# RP2350 register map
Vendor: Raspberry Pi; Series: RP; File version: 0.1
CPU: CM33 r1p0, little endian, MPU, FPU, DSP, VTOR, 4 interrupt priority bits, 52 interrupts, 8 SAU regions
Registers are 32-bit, read-write, reset 0x0 unless marked. A register's access mark holds for its fields unless they carry their own. Offsets are from the block's base; [hi:lo] are bit positions; {n}, {i} and the like mark numbered series; 'fields as' and 'values as' point back to an identical list.

## CLOCKS
Base 0x40010000
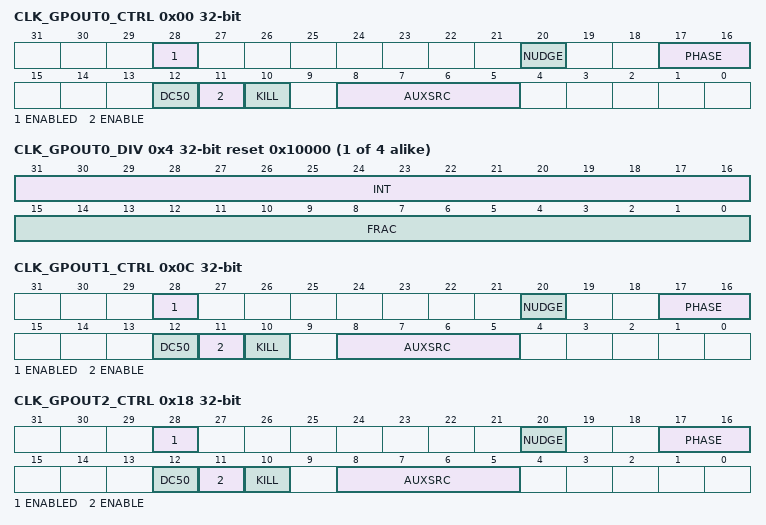
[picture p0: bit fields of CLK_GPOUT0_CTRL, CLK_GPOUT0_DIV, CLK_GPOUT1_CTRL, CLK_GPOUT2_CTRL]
0x00 CLK_GPOUT0_CTRL — Clock control, can be changed on-the-fly (except for auxsrc)
  [28] ENABLED ro — clock generator is enabled
  [20] NUDGE — An edge on this signal shifts the phase of the output by 1 cycle of the input clock This can be done at any time
  [17:16] PHASE — This delays the enable signal by up to 3 cycles of the input clock This must be set before the clock is enabled to have any effect
  [12] DC50 — Enables duty cycle correction for odd divisors, can be changed on-the-fly
  [11] ENABLE — Starts and stops the clock generator cleanly
  [10] KILL — Asynchronously kills the clock generator, enable must be set low before deasserting kill
  [8:5] AUXSRC — Selects the auxiliary clock source, will glitch when switching
    0=clksrc_pll_sys; 1=clksrc_gpin0; 2=clksrc_gpin1; 3=clksrc_pll_usb; 4=clksrc_pll_usb_primary_ref_opcg; 5=rosc_clksrc; 6=xosc_clksrc; 7=lposc_clksrc; 8=clk_sys; 9=clk_usb; 10=clk_adc; 11=clk_ref; 12=clk_peri; 13=clk_hstx; 14=otp_clk2fc
{0x4+0xC*i} CLK_GPOUT{i}_DIV reset 0x10000 (i=0..3)
  [31:16] INT — Integer part of clock divisor, 0 -> max+1, can be changed on-the-fly
  [15:0] FRAC — Fractional component of the divisor, can be changed on-the-fly
{0x8+0xC*i} CLK_GPOUT{i}_SELECTED reset 0x1 (i=0..3) — Indicates which src is currently selected (one-hot)
  [0] CLK_GPOUT{i}_SELECTED ro — This slice does not have a glitchless mux (only the AUX_SRC field is present, not SRC) so this register is hardwired to 0x1.
0x0C CLK_GPOUT1_CTRL — Clock control, can be changed on-the-fly (except for auxsrc)
  fields as CLK_GPOUT0_CTRL
0x18 CLK_GPOUT2_CTRL — Clock control, can be changed on-the-fly (except for auxsrc)
  [28] ENABLED ro — clock generator is enabled
  [20] NUDGE — An edge on this signal shifts the phase of the output by 1 cycle of the input clock This can be done at any time
  [17:16] PHASE — This delays the enable signal by up to 3 cycles of the input clock This must be set before the clock is enabled to have any effect
  [12] DC50 — Enables duty cycle correction for odd divisors, can be changed on-the-fly
  [11] ENABLE — Starts and stops the clock generator cleanly
  [10] KILL — Asynchronously kills the clock generator, enable must be set low before deasserting kill
  [8:5] AUXSRC — Selects the auxiliary clock source, will glitch when switching
    0=clksrc_pll_sys; 1=clksrc_gpin0; 2=clksrc_gpin1; 3=clksrc_pll_usb; 4=clksrc_pll_usb_primary_ref_opcg; 5=rosc_clksrc_ph; 6=xosc_clksrc; 7=lposc_clksrc; 8=clk_sys; 9=clk_usb; 10=clk_adc; 11=clk_ref; 12=clk_peri; 13=clk_hstx; 14=otp_clk2fc
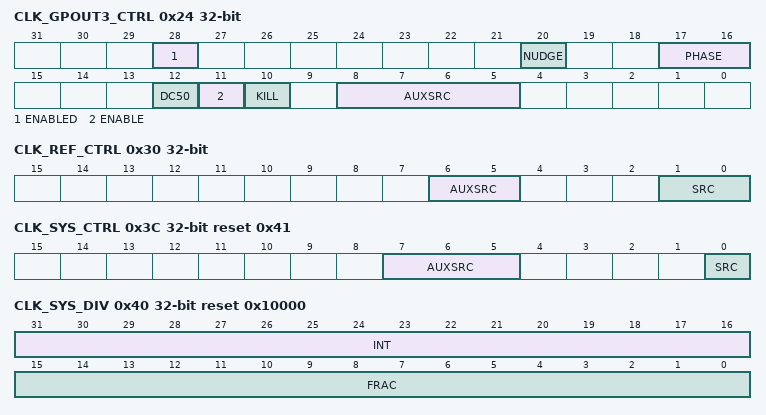
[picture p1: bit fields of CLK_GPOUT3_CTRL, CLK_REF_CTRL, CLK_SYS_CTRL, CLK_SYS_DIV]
0x24 CLK_GPOUT3_CTRL — Clock control, can be changed on-the-fly (except for auxsrc)
  fields as CLK_GPOUT2_CTRL
0x30 CLK_REF_CTRL — Clock control, can be changed on-the-fly (except for auxsrc)
  [6:5] AUXSRC — Selects the auxiliary clock source, will glitch when switching
    0=clksrc_pll_usb; 1=clksrc_gpin0; 2=clksrc_gpin1; 3=clksrc_pll_usb_primary_ref_opcg
  [1:0] SRC — Selects the clock source glitchlessly, can be changed on-the-fly
    0=rosc_clksrc_ph; 1=clksrc_clk_ref_aux; 2=xosc_clksrc; 3=lposc_clksrc
0x34 CLK_REF_DIV reset 0x10000
  [23:16] INT — Integer part of clock divisor, 0 -> max+1, can be changed on-the-fly
0x38 CLK_REF_SELECTED reset 0x1 — Indicates which src is currently selected (one-hot)
  [3:0] CLK_REF_SELECTED ro — The glitchless multiplexer does not switch instantaneously (to avoid glitches), so software should poll this register to wait for the switch to complete. This register contains one decoded bit for each of the clock sources enumerated in the CTRL SRC field. At most one of these bits will be set at any time, indicating that clock is currently present at the output of the glitchless mux. Whilst switching is in progress, this register may briefly show all-0s.
0x3C CLK_SYS_CTRL reset 0x41 — Clock control, can be changed on-the-fly (except for auxsrc)
  [7:5] AUXSRC — Selects the auxiliary clock source, will glitch when switching
    0=clksrc_pll_sys; 1=clksrc_pll_usb; 2=rosc_clksrc; 3=xosc_clksrc; 4=clksrc_gpin0; 5=clksrc_gpin1
  [0] SRC — Selects the clock source glitchlessly, can be changed on-the-fly
    0=clk_ref; 1=clksrc_clk_sys_aux
0x40 CLK_SYS_DIV reset 0x10000
  fields as CLK_GPOUT0_DIV
0x44 CLK_SYS_SELECTED reset 0x1 — Indicates which src is currently selected (one-hot)
  [1:0] CLK_SYS_SELECTED ro — The glitchless multiplexer does not switch instantaneously (to avoid glitches), so software should poll this register to wait for the switch to complete. This register contains one decoded bit for each of the clock sources enumerated in the CTRL SRC field. At most one of these bits will be set at any time, indicating that clock is currently present at the output of the glitchless mux. Whilst switching is in progress, this register may briefly show all-0s.
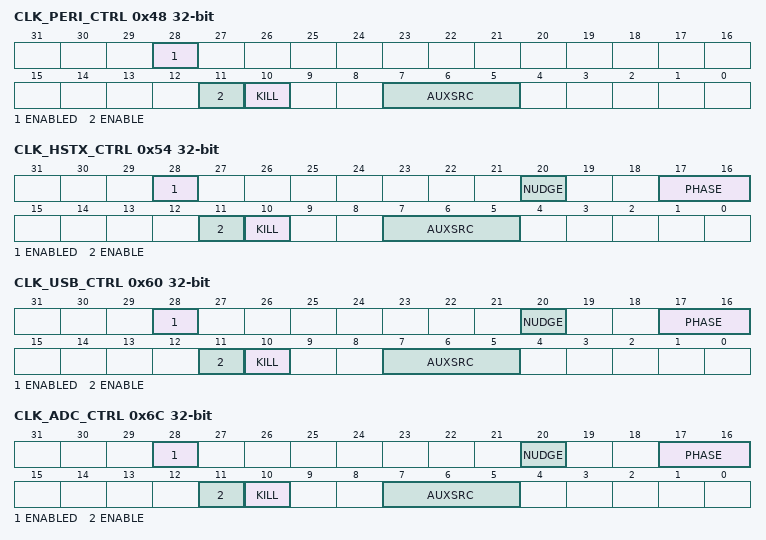
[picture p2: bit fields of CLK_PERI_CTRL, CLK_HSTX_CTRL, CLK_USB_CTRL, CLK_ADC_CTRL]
0x48 CLK_PERI_CTRL — Clock control, can be changed on-the-fly (except for auxsrc)
  [28] ENABLED ro — clock generator is enabled
  [11] ENABLE — Starts and stops the clock generator cleanly
  [10] KILL — Asynchronously kills the clock generator, enable must be set low before deasserting kill
  [7:5] AUXSRC — Selects the auxiliary clock source, will glitch when switching
    0=clk_sys; 1=clksrc_pll_sys; 2=clksrc_pll_usb; 3=rosc_clksrc_ph; 4=xosc_clksrc; 5=clksrc_gpin0; 6=clksrc_gpin1
0x4C CLK_PERI_DIV reset 0x10000
  [17:16] INT — Integer part of clock divisor, 0 -> max+1, can be changed on-the-fly
0x50 CLK_PERI_SELECTED reset 0x1 — Indicates which src is currently selected (one-hot)
  [0] CLK_PERI_SELECTED ro — This slice does not have a glitchless mux (only the AUX_SRC field is present, not SRC) so this register is hardwired to 0x1.
0x54 CLK_HSTX_CTRL — Clock control, can be changed on-the-fly (except for auxsrc)
  [28] ENABLED ro — clock generator is enabled
  [20] NUDGE — An edge on this signal shifts the phase of the output by 1 cycle of the input clock This can be done at any time
  [17:16] PHASE — This delays the enable signal by up to 3 cycles of the input clock This must be set before the clock is enabled to have any effect
  [11] ENABLE — Starts and stops the clock generator cleanly
  [10] KILL — Asynchronously kills the clock generator, enable must be set low before deasserting kill
  [7:5] AUXSRC — Selects the auxiliary clock source, will glitch when switching
    0=clk_sys; 1=clksrc_pll_sys; 2=clksrc_pll_usb; 3=clksrc_gpin0; 4=clksrc_gpin1
0x58 CLK_HSTX_DIV reset 0x10000
  fields as CLK_PERI_DIV
0x5C CLK_HSTX_SELECTED reset 0x1 — Indicates which src is currently selected (one-hot)
  [0] CLK_HSTX_SELECTED ro — This slice does not have a glitchless mux (only the AUX_SRC field is present, not SRC) so this register is hardwired to 0x1.
0x60 CLK_USB_CTRL — Clock control, can be changed on-the-fly (except for auxsrc)
  [28] ENABLED ro — clock generator is enabled
  [20] NUDGE — An edge on this signal shifts the phase of the output by 1 cycle of the input clock This can be done at any time
  [17:16] PHASE — This delays the enable signal by up to 3 cycles of the input clock This must be set before the clock is enabled to have any effect
  [11] ENABLE — Starts and stops the clock generator cleanly
  [10] KILL — Asynchronously kills the clock generator, enable must be set low before deasserting kill
  [7:5] AUXSRC — Selects the auxiliary clock source, will glitch when switching
    0=clksrc_pll_usb; 1=clksrc_pll_sys; 2=rosc_clksrc_ph; 3=xosc_clksrc; 4=clksrc_gpin0; 5=clksrc_gpin1
0x64 CLK_USB_DIV reset 0x10000
  [19:16] INT — Integer part of clock divisor, 0 -> max+1, can be changed on-the-fly
0x68 CLK_USB_SELECTED reset 0x1 — Indicates which src is currently selected (one-hot)
  [0] CLK_USB_SELECTED ro — This slice does not have a glitchless mux (only the AUX_SRC field is present, not SRC) so this register is hardwired to 0x1.
0x6C CLK_ADC_CTRL — Clock control, can be changed on-the-fly (except for auxsrc)
  fields as CLK_USB_CTRL
0x70 CLK_ADC_DIV reset 0x10000
  fields as CLK_USB_DIV
0x74 CLK_ADC_SELECTED reset 0x1 — Indicates which src is currently selected (one-hot)
  [0] CLK_ADC_SELECTED ro — This slice does not have a glitchless mux (only the AUX_SRC field is present, not SRC) so this register is hardwired to 0x1.
0x78 DFTCLK_XOSC_CTRL
  [1:0] SRC
    0=NULL; 1=clksrc_pll_usb_primary; 2=clksrc_gpin0
0x7C DFTCLK_ROSC_CTRL
  [1:0] SRC
    0=NULL; 1=clksrc_pll_sys_primary_rosc; 2=clksrc_gpin1
0x80 DFTCLK_LPOSC_CTRL
  [1:0] SRC
    0=NULL; 1=clksrc_pll_usb_primary_lposc; 2=clksrc_gpin1
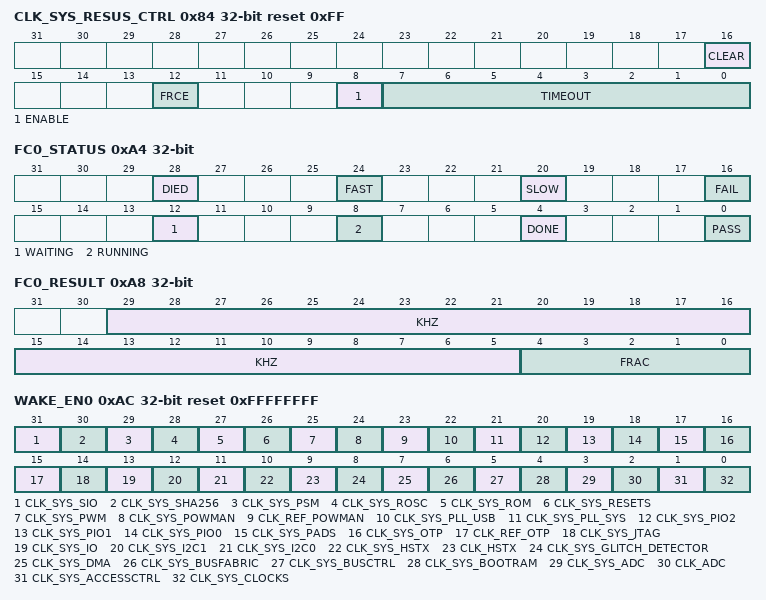
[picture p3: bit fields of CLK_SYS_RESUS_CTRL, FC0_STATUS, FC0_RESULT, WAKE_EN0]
0x84 CLK_SYS_RESUS_CTRL reset 0xFF
  [16] CLEAR — For clearing the resus after the fault that triggered it has been corrected
  [12] FRCE — Force a resus, for test purposes only
  [8] ENABLE — Enable resus
  [7:0] TIMEOUT — This is expressed as a number of clk_ref cycles and must be >= 2x clk_ref_freq/min_clk_tst_freq
0x88 CLK_SYS_RESUS_STATUS
  [0] RESUSSED ro — Clock has been resuscitated, correct the error then send ctrl_clear=1
0x8C FC0_REF_KHZ — Reference clock frequency in kHz
  [19:0] FC0_REF_KHZ
0x90 FC0_MIN_KHZ — Minimum pass frequency in kHz. This is optional. Set to 0 if you are not using the pass/fail flags
  [24:0] FC0_MIN_KHZ
0x94 FC0_MAX_KHZ reset 0x1FFFFFF — Maximum pass frequency in kHz. This is optional. Set to 0x1ffffff if you are not using the pass/fail flags
  [24:0] FC0_MAX_KHZ
0x98 FC0_DELAY reset 0x1 — Delays the start of frequency counting to allow the mux to settle Delay is measured in multiples of the reference clock period
  [2:0] FC0_DELAY
0x9C FC0_INTERVAL reset 0x8 — The test interval is 0.98us * 2**interval, but let's call it 1us * 2**interval The default gives a test interval of 250us
  [3:0] FC0_INTERVAL
0xA0 FC0_SRC — Clock sent to frequency counter, set to 0 when not required Writing to this register initiates the frequency count
  [7:0] FC0_SRC
    0=NULL; 1=pll_sys_clksrc_primary; 2=pll_usb_clksrc_primary; 3=rosc_clksrc; 4=rosc_clksrc_ph; 5=xosc_clksrc; 6=clksrc_gpin0; 7=clksrc_gpin1; 8=clk_ref; 9=clk_sys; 10=clk_peri; 11=clk_usb; 12=clk_adc; 13=clk_hstx; 14=lposc_clksrc; 15=otp_clk2fc; 16=pll_usb_clksrc_primary_dft
0xA4 FC0_STATUS — Frequency counter status
  [28] DIED ro — Test clock stopped during test
  [24] FAST ro — Test clock faster than expected, only valid when status_done=1
  [20] SLOW ro — Test clock slower than expected, only valid when status_done=1
  [16] FAIL ro — Test failed
  [12] WAITING ro — Waiting for test clock to start
  [8] RUNNING ro — Test running
  [4] DONE ro — Test complete
  [0] PASS ro — Test passed
0xA8 FC0_RESULT — Result of frequency measurement, only valid when status_done=1
  [29:5] KHZ ro, [4:0] FRAC ro
0xAC WAKE_EN0 reset 0xFFFFFFFF — enable clock in wake mode
  [31] CLK_SYS_SIO, [30] CLK_SYS_SHA256, [29] CLK_SYS_PSM, [28] CLK_SYS_ROSC, [27] CLK_SYS_ROM, [26] CLK_SYS_RESETS, [25] CLK_SYS_PWM, [24] CLK_SYS_POWMAN, [23] CLK_REF_POWMAN, [22] CLK_SYS_PLL_USB, [21] CLK_SYS_PLL_SYS, [20] CLK_SYS_PIO2, [19] CLK_SYS_PIO1, [18] CLK_SYS_PIO0, [17] CLK_SYS_PADS, [16] CLK_SYS_OTP, [15] CLK_REF_OTP, [14] CLK_SYS_JTAG, [13] CLK_SYS_IO, [12] CLK_SYS_I2C1, [11] CLK_SYS_I2C0, [10] CLK_SYS_HSTX, [9] CLK_HSTX, [8] CLK_SYS_GLITCH_DETECTOR, [7] CLK_SYS_DMA, [6] CLK_SYS_BUSFABRIC, [5] CLK_SYS_BUSCTRL, [4] CLK_SYS_BOOTRAM, [3] CLK_SYS_ADC, [2] CLK_ADC, [1] CLK_SYS_ACCESSCTRL, [0] CLK_SYS_CLOCKS
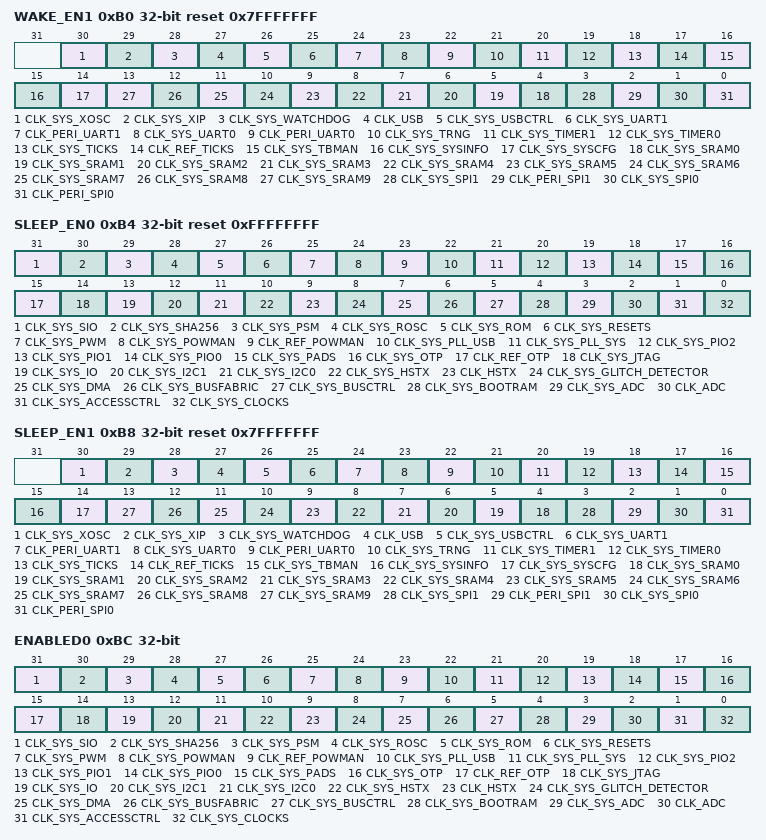
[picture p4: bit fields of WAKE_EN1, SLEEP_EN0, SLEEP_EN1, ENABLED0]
0xB0 WAKE_EN1 reset 0x7FFFFFFF — enable clock in wake mode
  [30] CLK_SYS_XOSC, [29] CLK_SYS_XIP, [28] CLK_SYS_WATCHDOG, [27] CLK_USB, [26] CLK_SYS_USBCTRL, [25] CLK_SYS_UART1, [24] CLK_PERI_UART1, [23] CLK_SYS_UART0, [22] CLK_PERI_UART0, [21] CLK_SYS_TRNG, [20] CLK_SYS_TIMER1, [19] CLK_SYS_TIMER0, [18] CLK_SYS_TICKS, [17] CLK_REF_TICKS, [16] CLK_SYS_TBMAN, [15] CLK_SYS_SYSINFO, [14] CLK_SYS_SYSCFG, [n+4] CLK_SYS_SRAM{n} (n=0..9), [3] CLK_SYS_SPI1, [2] CLK_PERI_SPI1, [1] CLK_SYS_SPI0, [0] CLK_PERI_SPI0
0xB4 SLEEP_EN0 reset 0xFFFFFFFF — enable clock in sleep mode
  fields as WAKE_EN0
0xB8 SLEEP_EN1 reset 0x7FFFFFFF — enable clock in sleep mode
  fields as WAKE_EN1
0xBC ENABLED0 — indicates the state of the clock enable
  [31] CLK_SYS_SIO ro, [30] CLK_SYS_SHA256 ro, [29] CLK_SYS_PSM ro, [28] CLK_SYS_ROSC ro, [27] CLK_SYS_ROM ro, [26] CLK_SYS_RESETS ro, [25] CLK_SYS_PWM ro, [24] CLK_SYS_POWMAN ro, [23] CLK_REF_POWMAN ro, [22] CLK_SYS_PLL_USB ro, [21] CLK_SYS_PLL_SYS ro, [20] CLK_SYS_PIO2 ro, [19] CLK_SYS_PIO1 ro, [18] CLK_SYS_PIO0 ro, [17] CLK_SYS_PADS ro, [16] CLK_SYS_OTP ro, [15] CLK_REF_OTP ro, [14] CLK_SYS_JTAG ro, [13] CLK_SYS_IO ro, [12] CLK_SYS_I2C1 ro, [11] CLK_SYS_I2C0 ro, [10] CLK_SYS_HSTX ro, [9] CLK_HSTX ro, [8] CLK_SYS_GLITCH_DETECTOR ro, [7] CLK_SYS_DMA ro, [6] CLK_SYS_BUSFABRIC ro, [5] CLK_SYS_BUSCTRL ro, [4] CLK_SYS_BOOTRAM ro, [3] CLK_SYS_ADC ro, [2] CLK_ADC ro, [1] CLK_SYS_ACCESSCTRL ro, [0] CLK_SYS_CLOCKS ro
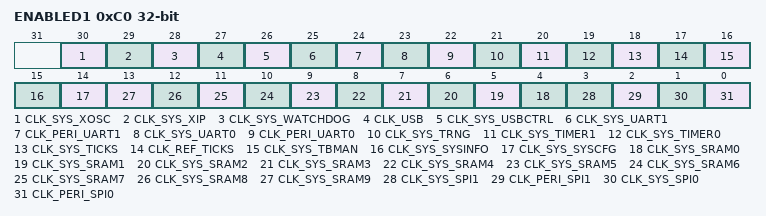
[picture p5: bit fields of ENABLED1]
0xC0 ENABLED1 — indicates the state of the clock enable
  [30] CLK_SYS_XOSC ro, [29] CLK_SYS_XIP ro, [28] CLK_SYS_WATCHDOG ro, [27] CLK_USB ro, [26] CLK_SYS_USBCTRL ro, [25] CLK_SYS_UART1 ro, [24] CLK_PERI_UART1 ro, [23] CLK_SYS_UART0 ro, [22] CLK_PERI_UART0 ro, [21] CLK_SYS_TRNG ro, [20] CLK_SYS_TIMER1 ro, [19] CLK_SYS_TIMER0 ro, [18] CLK_SYS_TICKS ro, [17] CLK_REF_TICKS ro, [16] CLK_SYS_TBMAN ro, [15] CLK_SYS_SYSINFO ro, [14] CLK_SYS_SYSCFG ro, [n+4] CLK_SYS_SRAM{n} ro (n=0..9), [3] CLK_SYS_SPI1 ro, [2] CLK_PERI_SPI1 ro, [1] CLK_SYS_SPI0 ro, [0] CLK_PERI_SPI0 ro
0xC4 INTR — Raw Interrupts
  [0] CLK_SYS_RESUS ro
0xC8 INTE — Interrupt Enable
  [0] CLK_SYS_RESUS
0xCC INTF — Interrupt Force
  [0] CLK_SYS_RESUS
0xD0 INTS — Interrupt status after masking & forcing
  [0] CLK_SYS_RESUS ro

## Notices in the file
Copyright (c) 2024 Raspberry Pi Ltd.
SPDX-License-Identifier: BSD-3-Clause
Copyright (c) 2024 Raspberry Pi Ltd. SPDX-License-Identifier: BSD-3-Clause
